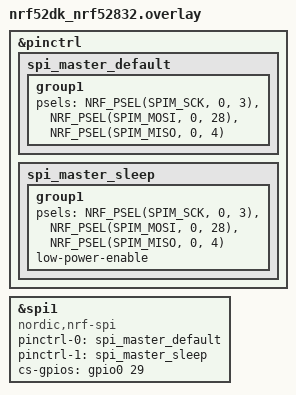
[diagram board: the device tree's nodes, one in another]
&pinctrl {
	spi_master_default: spi_master_default {
		group1 {
			psels = <NRF_PSEL(SPIM_SCK, 0, 3)>,
					<NRF_PSEL(SPIM_MOSI, 0, 28)>,
					<NRF_PSEL(SPIM_MISO, 0, 4)>;
		};
	};

	spi_master_sleep: spi_master_sleep {
		group1 {
			psels = <NRF_PSEL(SPIM_SCK, 0, 3)>,
					<NRF_PSEL(SPIM_MOSI, 0, 28)>,
					<NRF_PSEL(SPIM_MISO, 0, 4)>;
			low-power-enable;
		};
	};
};

spi1_master: &spi1 {
	compatible = "nordic,nrf-spi";
	status = "okay";
	pinctrl-0 = <&spi_master_default>;
	pinctrl-1 = <&spi_master_sleep>;
	pinctrl-names = "default", "sleep";
	cs-gpios = <&gpio0 29 GPIO_ACTIVE_HIGH>;
};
